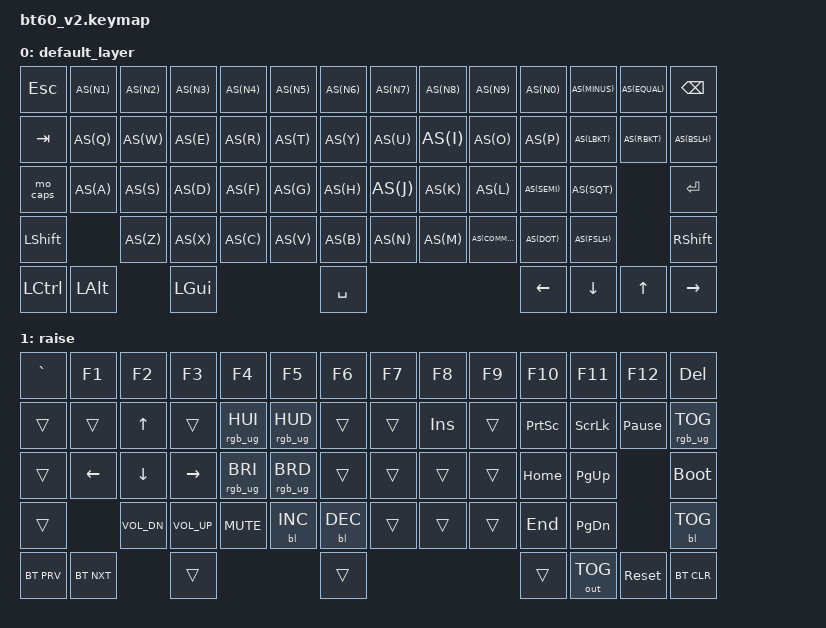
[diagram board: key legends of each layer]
#include <behaviors.dtsi>
#include <dt-bindings/zmk/backlight.h>
#include <dt-bindings/zmk/bt.h>
#include <dt-bindings/zmk/keys.h>
#include <dt-bindings/zmk/rgb.h>
#include <dt-bindings/zmk/outputs.h>

#define AS(keycode) &as LS(keycode) keycode

/ {
    behaviors {
        as: as {
            compatible = "zmk,behavior-hold-tap";
            label = "Auto-Shift";
            bindings = <&kp>, <&kp>;

            #binding-cells = <2>;
            tapping-term-ms = <180>;
            flavor = "tap-preferred";
        };

        mo_caps: mo_caps {
            compatible = "zmk,behavior-tap-dance";
            label = "Momentary Layer / Caps Lock";
            bindings = <&mo 1>, <&caps_word>;

            #binding-cells = <0>;
            tapping-term-ms = <200>;
        };
    };

    keymap {
        compatible = "zmk,keymap";

        default_layer {
            // ------------------------------------------------------------------------------------------
            // | ESC |  1  |  2  |  3  |  4  |  5  |  6  |  7  |  8  |  9  |  0  |  -  |  =  |   BSPC   |
            // | TAB  |  Q  |  W  |  E  |  R  |  T  |  Y  |  U  |  I  |  O  |  P  |  [  |  ]  |   \     |
            // | CAPS  |  A  |  S  |  D  |  F  |  G  |  H  |  J  |  K  |  L  |  ;  |  '  |     ENTER    |
            // |  SHIFT    |  Z  |  X  |  C  |  V  |  B  |  N  |  M  |  ,  |  .  | /   |      SHIFT     |
            // |  CTL  |  WIN  |  ALT  |            SPACE               | ALT |   1  |  MENU   |  CTRL  |
            // ------------------------------------------------------------------------------------------

            bindings = <
&kp ESC    AS(N1)    AS(N2)  AS(N3)    AS(N4)  AS(N5)  AS(N6)     AS(N7)  AS(N8)  AS(N9)     AS(N0)    AS(MINUS)  AS(EQUAL)  &kp BSPC
&kp TAB    AS(Q)     AS(W)   AS(E)     AS(R)   AS(T)   AS(Y)      AS(U)   AS(I)   AS(O)      AS(P)     AS(LBKT)   AS(RBKT)   AS(BSLH)
&mo_caps   AS(A)     AS(S)   AS(D)     AS(F)   AS(G)   AS(H)      AS(J)   AS(K)   AS(L)      AS(SEMI)  AS(SQT)               &kp RET
&kp LSHFT            AS(Z)   AS(X)     AS(C)   AS(V)   AS(B)      AS(N)   AS(M)   AS(COMMA)  AS(DOT)   AS(FSLH)              &kp RSHFT
&kp LCTRL  &kp LALT          &kp LGUI                  &kp SPACE                             &kp LEFT  &kp DOWN   &kp UP     &kp RIGHT
            >;
        };

        raise {
            // ------------------------------------------------------------------------------------------
            // |GRAVE| F1  | F2  | F3  | F4  | F5  | F6  | F7  | F8  | F9  | F10 | F11 | F12 |    DEL   |
            // | TAB  |  Q  | UP  |  E  | HUI | HUD |  Y  |  U  | INS |  O  |PSCRN| SLCK| P_B |  RGB_TOG|
            // | CAPS  | LEFT| DOWN|RIGHT| BRI | BRD |  H  |  J  |  K  |  L  | HOME| PGUP|     BOOT     |
            // |  SHIFT   |VOLDN|VOLUP| MUTE|BLINC|BLDEC|  N  |  M  |  ,  | END | PGDN |      BL_TOG    |
            // | BT_PRV| BT_NXT|  ALT  |            SPACE               | ALT | OUT_TG | RESET | BT_CLR |
            // ------------------------------------------------------------------------------------------

            bindings = <
&kp GRAVE   &kp F1      &kp F2        &kp F3        &kp F4           &kp F5           &kp F6      &kp F7  &kp F8   &kp F9  &kp F10    &kp F11    &kp F12          &kp DEL
&trans      &trans      &kp UP        &trans        &rgb_ug RGB_HUI  &rgb_ug RGB_HUD  &trans      &trans  &kp INS  &trans  &kp PSCRN  &kp SLCK   &kp PAUSE_BREAK  &rgb_ug RGB_TOG
&trans      &kp LEFT    &kp DOWN      &kp RIGHT     &rgb_ug RGB_BRI  &rgb_ug RGB_BRD  &trans      &trans  &trans   &trans  &kp HOME   &kp PG_UP                   &bootloader
&trans                  &kp C_VOL_DN  &kp C_VOL_UP  &kp C_MUTE       &bl BL_INC       &bl BL_DEC  &trans  &trans   &trans  &kp END    &kp PG_DN                   &bl BL_TOG
&bt BT_PRV  &bt BT_NXT                &trans                                          &trans                               &trans   &out OUT_TOG &sys_reset       &bt BT_CLR
            >;
        };
    };
};
